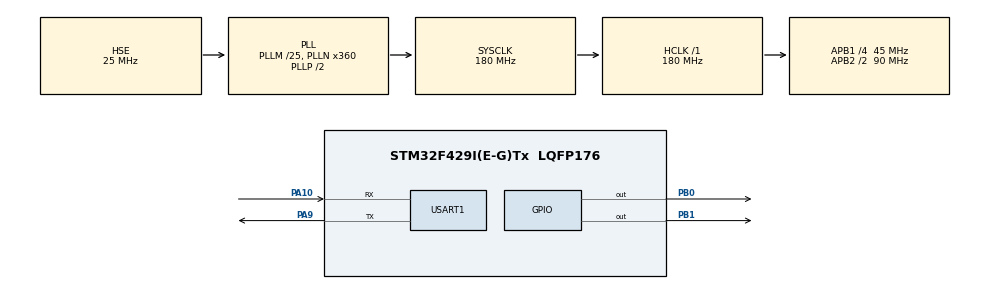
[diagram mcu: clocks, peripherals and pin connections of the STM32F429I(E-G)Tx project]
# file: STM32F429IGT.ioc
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Mcu.Family=STM32F4
Mcu.Name=STM32F429I(E-G)Tx
Mcu.Package=LQFP176
NVIC.PriorityGroup=NVIC_PRIORITYGROUP_4
PA0/WKUP.Mode=SYS_WakeUp0
PA0/WKUP.Signal=SYS_WKUP
PA10.Mode=Asynchronous
PA10.Signal=USART1_RX
PA13.Mode=Trace_Synchro_4bits_JTAG
PA13.Signal=SYS_JTMS-SWDIO
PA14.Mode=Trace_Synchro_4bits_JTAG
PA14.Signal=SYS_JTCK-SWCLK
PA15.Mode=Trace_Synchro_4bits_JTAG
PA15.Signal=SYS_JTDI
PA9.Mode=Asynchronous
PA9.Signal=USART1_TX
PB0.GPIO_PuPd=GPIO_PULLUP
PB0.GPIO_Speed=GPIO_SPEED_FREQ_HIGH
PB0.PinState=GPIO_PIN_SET
PB0.Signal=GPIO_Output
PB1.GPIO_Speed=GPIO_SPEED_FREQ_HIGH
PB1.Signal=GPIO_Output
PB3.Mode=Trace_Synchro_4bits_JTAG
PB3.Signal=SYS_JTDO-SWO
PC14/OSC32_IN.Mode=LSE-External-Oscillator
PC14/OSC32_IN.Signal=RCC_OSC32_IN
PC15/OSC32_OUT.Mode=LSE-External-Oscillator
PC15/OSC32_OUT.Signal=RCC_OSC32_OUT
PE2.Mode=Trace_Synchro_4bits_JTAG
PE2.Signal=SYS_TRACECLK
PE3.Mode=Trace_Synchro_4bits_JTAG
PE3.Signal=SYS_TRACED0
PE4.Mode=Trace_Synchro_4bits_JTAG
PE4.Signal=SYS_TRACED1
PE5.Mode=Trace_Synchro_4bits_JTAG
PE5.Signal=SYS_TRACED2
PE6.Mode=Trace_Synchro_4bits_JTAG
PE6.Signal=SYS_TRACED3
PH0/OSC_IN.Mode=HSE-External-Oscillator
PH0/OSC_IN.Signal=RCC_OSC_IN
PH1/OSC_OUT.Mode=HSE-External-Oscillator
PH1/OSC_OUT.Signal=RCC_OSC_OUT
ProjectManager.HeapSize=0x200
ProjectManager.StackSize=0x400
ProjectManager.TargetToolchain=MDK-ARM V5
RCC.48MHZClocksFreq_Value=90000000
RCC.AHBFreq_Value=180000000
RCC.APB1CLKDivider=RCC_HCLK_DIV4
RCC.APB1Freq_Value=45000000
RCC.APB1TimFreq_Value=90000000
RCC.APB2CLKDivider=RCC_HCLK_DIV2
RCC.APB2Freq_Value=90000000
RCC.APB2TimFreq_Value=180000000
RCC.CortexFreq_Value=180000000
RCC.HCLKFreq_Value=180000000
RCC.HSE_VALUE=25000000
RCC.HSI_VALUE=16000000
RCC.PLLI2SN=360
RCC.PLLM=25
RCC.PLLN=360
RCC.PLLSourceVirtual=RCC_PLLSOURCE_HSE
RCC.RCC_RTC_Clock_Source=RCC_RTCCLKSOURCE_LSE
RCC.RCC_RTC_Clock_SourceVirtual=RCC_RTCCLKSOURCE_LSE
RCC.SYSCLKFreq_VALUE=180000000
RCC.SYSCLKSource=RCC_SYSCLKSOURCE_PLLCLK
RCC.VCOOutputFreq_Value=360000000
USART1.VirtualMode=VM_ASYNC
VP_RTC_VS_RTC_Activate.Mode=RTC_Enabled
board=custom

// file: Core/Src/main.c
/* USER CODE BEGIN Header */
/**
  ******************************************************************************
  * @file           : main.c
  * @brief          : Main program body
  ******************************************************************************
  * @attention
  *
  * <h2><center>&copy; Copyright (c) 2019 STMicroelectronics.
  * All rights reserved.</center></h2>
  *
  * This software component is licensed by ST under BSD 3-Clause license,
  * the "License"; You may not use this file except in compliance with the
  * License. You may obtain a copy of the License at:
  *                        opensource.org/licenses/BSD-3-Clause
  *
  ******************************************************************************
  */
/* USER CODE END Header */

#include "main.h"

/* USER CODE BEGIN Includes */
#include "printf_support.h"
/* USER CODE END Includes */

RTC_HandleTypeDef hrtc;

UART_HandleTypeDef huart1;

void SystemClock_Config(void);
static void MX_GPIO_Init(void);
static void MX_RTC_Init(void);
static void MX_USART1_UART_Init(void);

int main(void)
{
  /* USER CODE BEGIN 1 */
  uint16_t count = 0;
  /* USER CODE END 1 */

  /* MCU Configuration--------------------------------------------------------*/

  /* Reset of all peripherals, Initializes the Flash interface and the Systick. */
  HAL_Init();

  /* Configure the system clock */
  SystemClock_Config();

  /* Initialize all configured peripherals */
  MX_GPIO_Init();
  MX_RTC_Init();
  MX_USART1_UART_Init();

  /* Infinite loop */
  /* USER CODE BEGIN WHILE */
  while (1)
  {
    HAL_GPIO_TogglePin(GPIOB, GPIO_PIN_0);
    HAL_GPIO_TogglePin(GPIOB, GPIO_PIN_1);
    count+=1;
		printf("%d\n", count);
		//fflush(stdout);//如果使用gcc编译器请在printf后面加上这个
		HAL_Delay(500);
    /* USER CODE END WHILE */

  }
}

void SystemClock_Config(void)
{
  RCC_OscInitTypeDef RCC_OscInitStruct = {0};
  RCC_ClkInitTypeDef RCC_ClkInitStruct = {0};
  RCC_PeriphCLKInitTypeDef PeriphClkInitStruct = {0};

  /** Configure the main internal regulator output voltage
  */
  __HAL_RCC_PWR_CLK_ENABLE();
  __HAL_PWR_VOLTAGESCALING_CONFIG(PWR_REGULATOR_VOLTAGE_SCALE1);
  /** Initializes the CPU, AHB and APB busses clocks
  */
  RCC_OscInitStruct.OscillatorType = RCC_OSCILLATORTYPE_HSE|RCC_OSCILLATORTYPE_LSE;
  RCC_OscInitStruct.HSEState = RCC_HSE_ON;
  RCC_OscInitStruct.LSEState = RCC_LSE_ON;
  RCC_OscInitStruct.PLL.PLLState = RCC_PLL_ON;
  RCC_OscInitStruct.PLL.PLLSource = RCC_PLLSOURCE_HSE;
  RCC_OscInitStruct.PLL.PLLM = 25;
  RCC_OscInitStruct.PLL.PLLN = 360;
  RCC_OscInitStruct.PLL.PLLP = RCC_PLLP_DIV2;
  RCC_OscInitStruct.PLL.PLLQ = 4;
  if (HAL_RCC_OscConfig(&RCC_OscInitStruct) != HAL_OK)
  {
    Error_Handler();
  }
  /** Activate the Over-Drive mode
  */
  if (HAL_PWREx_EnableOverDrive() != HAL_OK)
  {
    Error_Handler();
  }
  /** Initializes the CPU, AHB and APB busses clocks
  */
  RCC_ClkInitStruct.ClockType = RCC_CLOCKTYPE_HCLK|RCC_CLOCKTYPE_SYSCLK
                              |RCC_CLOCKTYPE_PCLK1|RCC_CLOCKTYPE_PCLK2;
  RCC_ClkInitStruct.SYSCLKSource = RCC_SYSCLKSOURCE_PLLCLK;
  RCC_ClkInitStruct.AHBCLKDivider = RCC_SYSCLK_DIV1;
  RCC_ClkInitStruct.APB1CLKDivider = RCC_HCLK_DIV4;
  RCC_ClkInitStruct.APB2CLKDivider = RCC_HCLK_DIV2;

  if (HAL_RCC_ClockConfig(&RCC_ClkInitStruct, FLASH_LATENCY_5) != HAL_OK)
  {
    Error_Handler();
  }
  PeriphClkInitStruct.PeriphClockSelection = RCC_PERIPHCLK_RTC;
  PeriphClkInitStruct.RTCClockSelection = RCC_RTCCLKSOURCE_LSE;
  if (HAL_RCCEx_PeriphCLKConfig(&PeriphClkInitStruct) != HAL_OK)
  {
    Error_Handler();
  }
}

static void MX_RTC_Init(void)
{

  /** Initialize RTC Only
  */
  hrtc.Instance = RTC;
  hrtc.Init.HourFormat = RTC_HOURFORMAT_24;
  hrtc.Init.AsynchPrediv = 127;
  hrtc.Init.SynchPrediv = 255;
  hrtc.Init.OutPut = RTC_OUTPUT_DISABLE;
  hrtc.Init.OutPutPolarity = RTC_OUTPUT_POLARITY_HIGH;
  hrtc.Init.OutPutType = RTC_OUTPUT_TYPE_OPENDRAIN;
  if (HAL_RTC_Init(&hrtc) != HAL_OK)
  {
    Error_Handler();
  }

}

static void MX_USART1_UART_Init(void)
{

  huart1.Instance = USART1;
  huart1.Init.BaudRate = 115200;
  huart1.Init.WordLength = UART_WORDLENGTH_8B;
  huart1.Init.StopBits = UART_STOPBITS_1;
  huart1.Init.Parity = UART_PARITY_NONE;
  huart1.Init.Mode = UART_MODE_TX_RX;
  huart1.Init.HwFlowCtl = UART_HWCONTROL_NONE;
  huart1.Init.OverSampling = UART_OVERSAMPLING_16;
  if (HAL_UART_Init(&huart1) != HAL_OK)
  {
    Error_Handler();
  }

}

static void MX_GPIO_Init(void)
{
  GPIO_InitTypeDef GPIO_InitStruct = {0};

  /* GPIO Ports Clock Enable */
  __HAL_RCC_GPIOE_CLK_ENABLE();
  __HAL_RCC_GPIOC_CLK_ENABLE();
  __HAL_RCC_GPIOH_CLK_ENABLE();
  __HAL_RCC_GPIOA_CLK_ENABLE();
  __HAL_RCC_GPIOB_CLK_ENABLE();

  /*Configure GPIO pin Output Level */
  HAL_GPIO_WritePin(GPIOB, GPIO_PIN_0, GPIO_PIN_SET);

  /*Configure GPIO pin Output Level */
  HAL_GPIO_WritePin(GPIOB, GPIO_PIN_1, GPIO_PIN_RESET);

  /*Configure GPIO pin : PB0 */
  GPIO_InitStruct.Pin = GPIO_PIN_0;
  GPIO_InitStruct.Mode = GPIO_MODE_OUTPUT_PP;
  GPIO_InitStruct.Pull = GPIO_PULLUP;
  GPIO_InitStruct.Speed = GPIO_SPEED_FREQ_HIGH;
  HAL_GPIO_Init(GPIOB, &GPIO_InitStruct);

  /*Configure GPIO pin : PB1 */
  GPIO_InitStruct.Pin = GPIO_PIN_1;
  GPIO_InitStruct.Mode = GPIO_MODE_OUTPUT_PP;
  GPIO_InitStruct.Pull = GPIO_NOPULL;
  GPIO_InitStruct.Speed = GPIO_SPEED_FREQ_HIGH;
  HAL_GPIO_Init(GPIOB, &GPIO_InitStruct);

}

void Error_Handler(void)
{
}

/************************ (C) COPYRIGHT STMicroelectronics *****END OF FILE****/
